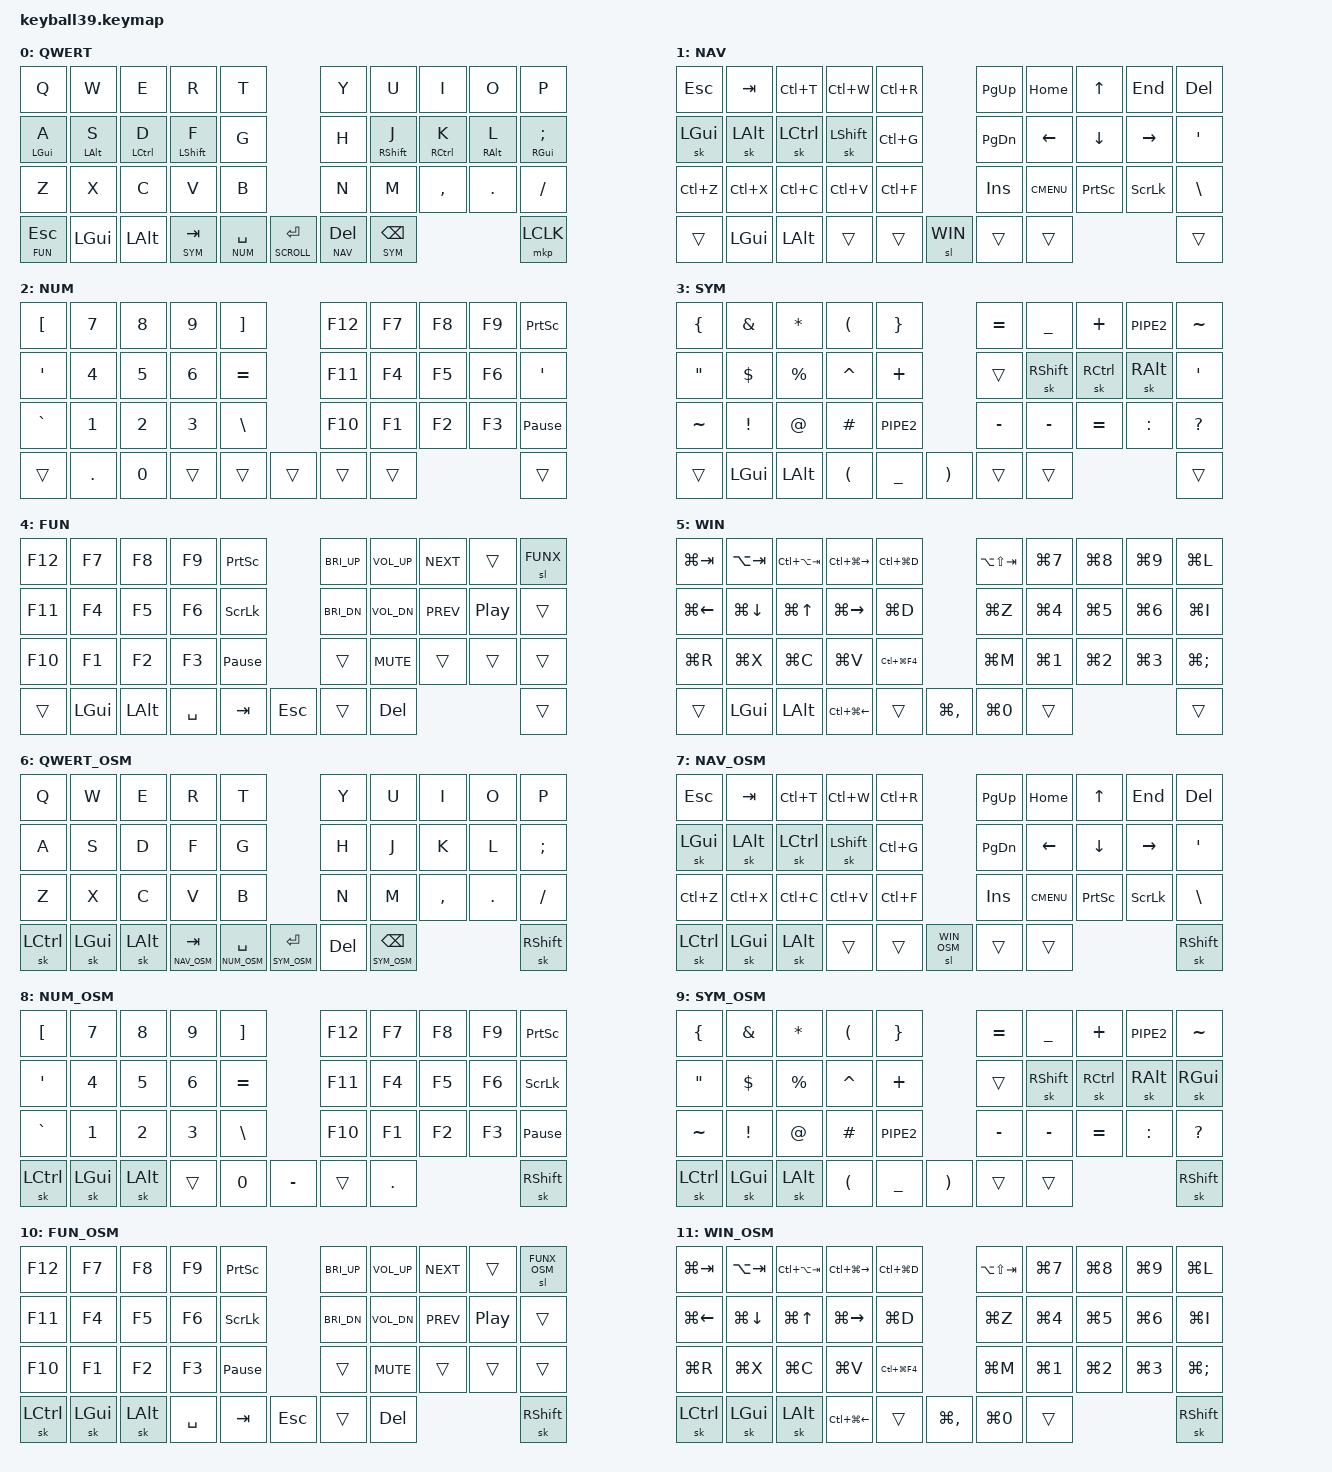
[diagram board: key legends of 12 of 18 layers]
/*
 * Copyright (c) 2020 The ZMK Contributors
 *
 * SPDX-License-Identifier: MIT
 */

#include <behaviors/mouse_keys.dtsi>
#include <dt-bindings/zmk/mouse.h>
#include <behaviors.dtsi>
#include <dt-bindings/zmk/keys.h>
#include <dt-bindings/zmk/bt.h>


// Layer definitions
#define BASE        0
#define NAV         1
#define NUM         2
#define SYM         3
#define FUN         4
#define WIN         5
#define BASE_OSM    6
#define NAV_OSM     7
#define NUM_OSM     8
#define SYM_OSM     9
#define FUN_OSM     10
#define WIN_OSM     11
#define FUNX        12
#define FUNX_OSM    13
#define ADJ         14
#define MOUSE       15
#define SCROLL      16
#define SNIPE       17



// Enhanced behavior configurations
&lt {
    tapping-term-ms = <180>;
    flavor = "balanced";
    quick-tap-ms = <180>;
    global-quick-tap;
};

&mt {
    tapping-term-ms = <180>;
    flavor = "balanced";
    quick-tap-ms = <180>;
    global-quick-tap;
    retro-tap;
};

&sk {
    release-after-ms = <2000>;
    quick-release;
};


/ {
    combos {
        compatible = "zmk,combos";

        // Universal escape
        combo_esc {
            timeout-ms = <40>;
            key-positions = <8 9>;
            bindings = <&kp ESC>;
        };

        // Quick tab access
        combo_tab {
            timeout-ms = <40>;
            key-positions = <0 1>;
            bindings = <&kp TAB>;
        };

        // Quick delete
        combo_del {
            timeout-ms = <40>;
            key-positions = <17 18>;
            bindings = <&kp DEL>;
        };


        // Programming brackets
        combo_lbkt {
            timeout-ms = <30>;
            key-positions = <3 4>;
            bindings = <&kp LBKT>;
        };

        combo_rbkt {
            timeout-ms = <30>;
            key-positions = <5 6>;
            bindings = <&kp RBKT>;
        };

        combo_lbrc {
            timeout-ms = <30>;
            key-positions = <13 14>;
            bindings = <&kp LBRC>;
        };
        combo_rbrc {
            timeout-ms = <30>;
            key-positions = <15 16>;
            bindings = <&kp RBRC>;
        };

        combo_lpar {
            timeout-ms = <30>;
            key-positions = <23 24>;
            bindings = <&kp LPAR>;
        };

        combo_rpar {
            timeout-ms = <30>;
            key-positions = <25 26>;
            bindings = <&kp RPAR>;
        };


        // Alt+Tab shortcuts
        combo_alt_tab {
            timeout-ms = <40>;
            key-positions = <1 2>;
            bindings = <&kp LA(TAB)>;
        };

        combo_alt_shift_tab {
            timeout-ms = <40>;
            key-positions = <2 3>;
            bindings = <&kp LA(LS(TAB))>;
        };
        // Windows shortcuts
        combo_win_left {
            timeout-ms = <30>;
            key-positions = <6 7>;
            bindings = <&kp LG(LEFT)>;
            layers = <NAV NAV_OSM>;
        };

        combo_win_right {
            timeout-ms = <30>;
            key-positions = <7 8>;
            bindings = <&kp LG(RIGHT)>;
            layers = <NAV NAV_OSM>;
        };

        // Windows management layer
        combo_win_layer {
            timeout-ms = <50>;
            key-positions = <34 35>;
            bindings = <&sl WIN>;
            layers = <BASE NAV NUM SYM FUN FUNX>;
        };

        combo_win_layer_osm {
            timeout-ms = <50>;
            key-positions = <34 35>;
            bindings = <&sl WIN_OSM>;
            layers = <BASE_OSM NAV_OSM NUM_OSM SYM_OSM FUN_OSM FUNX_OSM>;
        };

        // Adjustment layer
        combo_adj {
            timeout-ms = <50>;
            key-positions = <36 37>;
            bindings = <&mo ADJ>;
        };

        // Emergency return
        combo_base_return {
            timeout-ms = <100>;
            key-positions = <0 9>;
            bindings = <&to BASE>;
        };

        // Mouse click combos
        combo_left_click {
            timeout-ms = <50>;
            key-positions = <26 27>;  // N+M
            bindings = <&mkp LCLK>;
        };

        combo_right_click {
            timeout-ms = <50>;
            key-positions = <27 28>;  // M+,
            bindings = <&mkp RCLK>;
        };

        combo_middle_click {
            timeout-ms = <50>;
            key-positions = <26 27 28>;  // N+M+,
            bindings = <&mkp MCLK>;
        };

                // Adjustment layer
        combo_scroll {
            timeout-ms = <50>;
            key-positions = <26 17 28>;
            bindings = <&mo SCROLL>;
        };
                        // Adjustment layer
        combo_snipe {
            timeout-ms = <50>;
            key-positions = <26 27 28 29>;
            bindings = <&mo SNIPE>;
        };


        // Mouse click combos
        combo_left_clickL {
            timeout-ms = <50>;
            key-positions = <22 23>;  // N+M
            bindings = <&mkp LCLK>;
        };

        combo_right_clickL {
            timeout-ms = <50>;
            key-positions = <21 22>;  // M+,
            bindings = <&mkp RCLK>;
        };

        combo_middle_clickL {
            timeout-ms = <50>;
            key-positions = <21 22 23>;  // N+M+,
            bindings = <&mkp MCLK>;
        };

                // Adjustment layer
        combo_scrollL {
            timeout-ms = <50>;
            key-positions = <21 12 23>;
            bindings = <&mo SCROLL>;
        };
                        // Adjustment layer
        combo_snipeL {
            timeout-ms = <50>;
            key-positions = <20 21 22 23>;
            bindings = <&mo SNIPE>;
        };


    };

    macros {
        // Programming shortcuts
        arrow_fn: arrow_fn {
            compatible = "zmk,behavior-macro";
            #binding-cells = <0>;
            bindings = <&kp EQUAL &kp GT &kp SPACE>;
        };

        console_log: console_log {
            compatible = "zmk,behavior-macro";
            #binding-cells = <0>;
            bindings = <&kp C &kp O &kp N &kp S &kp O &kp L &kp E &kp DOT &kp L &kp O &kp G &kp LPAR>;
        };

        // Windows shortcuts
        win_run: win_run {
            compatible = "zmk,behavior-macro";
            #binding-cells = <0>;
            bindings = <&kp LG(R)>;
        };

        win_settings: win_settings {
            compatible = "zmk,behavior-macro";
            #binding-cells = <0>;
            bindings = <&kp LG(I)>;
        };

        win_lock: win_lock {
            compatible = "zmk,behavior-macro";
            #binding-cells = <0>;
            bindings = <&kp LG(L)>;
        };

        // Media control macros
        teams_mute: teams_mute {
            compatible = "zmk,behavior-macro";
            #binding-cells = <0>;
            bindings = <&kp LC(LS(M))>;
        };

        spotify_play_pause: spotify_play_pause {
            compatible = "zmk,behavior-macro";
            #binding-cells = <0>;
            bindings = <&kp C_PP>;
        };

        discord_mute: discord_mute {
            compatible = "zmk,behavior-macro";
            #binding-cells = <0>;
            bindings = <&kp LC(LS(M))>;
        };

        discord_deafen: discord_deafen {
            compatible = "zmk,behavior-macro";
            #binding-cells = <0>;
            bindings = <&kp LC(LS(D))>;
        };

        obs_start_stop: obs_start_stop {
            compatible = "zmk,behavior-macro";
            #binding-cells = <0>;
            bindings = <&kp F13>;
        };

        obs_pause: obs_pause {
            compatible = "zmk,behavior-macro";
            #binding-cells = <0>;
            bindings = <&kp F14>;
        };
    };

    keymap {
        compatible = "zmk,keymap";

        // Base layer with home row mods
        base_layer {
            label = "QWERT";
            bindings = <
&kp Q           &kp W           &kp E            &kp R             &kp T                                    &kp Y         &kp U             &kp I            &kp O           &kp P
&mt LGUI A      &mt LALT S      &mt LCTRL D      &mt LSHFT F       &kp G                                    &kp H         &mt RSHFT J       &mt RCTRL K      &mt RALT L      &mt RGUI SEMI
&kp Z           &kp X           &kp C            &kp V             &kp B                                    &kp N         &kp M             &kp COMMA        &kp DOT         &kp FSLH
&lt FUN ESC     &kp LGUI        &kp LALT         &lt SYM TAB       &lt NUM SPACE       &lt SCROLL RET       &lt NAV DEL       &lt SYM BSPC                                   &mkp LCLK
            >;
        };

        nav_layer {
            label = "NAV";
            bindings = <
&kp ESC         &kp TAB         &kp LC(T)        &kp LC(W)         &kp LC(R)                                &kp PG_UP     &kp HOME          &kp UP           &kp END         &kp DEL
&sk LGUI        &sk LALT        &sk LCTRL        &sk LSHFT         &kp LC(G)                                &kp PG_DN     &kp LEFT          &kp DOWN         &kp RIGHT       &kp SQT
&kp LC(Z)       &kp LC(X)       &kp LC(C)        &kp LC(V)         &kp LC(F)                                &kp INS       &kp K_CMENU       &kp PSCRN        &kp SCROLLLOCK  &kp BSLH
&trans          &kp LGUI        &kp LALT         &trans            &trans               &sl WIN             &trans        &trans                                             &trans
            >;
        };

        num_layer {
            label = "NUM";
            bindings = <
&kp LBKT        &kp N7          &kp N8           &kp N9            &kp RBKT                                 &kp F12       &kp F7            &kp F8           &kp F9          &kp PSCRN
&kp SQT         &kp N4          &kp N5           &kp N6            &kp EQUAL                                &kp F11       &kp F4            &kp F5           &kp F6          &kp SQT
&kp GRAVE       &kp N1          &kp N2           &kp N3            &kp BSLH                                 &kp F10       &kp F1            &kp F2           &kp F3          &kp PAUSE_BREAK
&trans          &kp DOT         &kp N0           &trans            &trans               &trans              &trans        &trans                                             &trans
            >;
        };

        sym_layer {
            label = "SYM";
            bindings = <
&kp LBRC        &kp AMPERSAND   &kp ASTERISK     &kp LPAR          &kp RBRC                                 &kp EQUAL     &kp UNDERSCORE    &kp PLUS         &kp PIPE2       &kp TILDE
&kp DQT         &kp DLLR        &kp PRCNT        &kp CARET         &kp PLUS                                 &trans        &sk RSHFT         &sk RCTRL        &sk RALT        &kp SQT
&kp TILDE       &kp EXCL        &kp AT           &kp HASH          &kp PIPE2                                &kp MINUS     &kp MINUS         &kp EQUAL        &kp COLON       &kp QMARK
&trans          &kp LGUI        &kp LALT         &kp LPAR          &kp UNDERSCORE       &kp RPAR            &trans        &trans                                         &trans
            >;
        };

        fun_layer {
            label = "FUN";
            bindings = <
&kp F12         &kp F7          &kp F8           &kp F9            &kp PSCRN                                &kp C_BRI_UP  &kp C_VOL_UP      &kp C_NEXT       &trans          &sl FUNX
&kp F11         &kp F4          &kp F5           &kp F6            &kp SLCK                                 &kp C_BRI_DN  &kp C_VOL_DN      &kp C_PREV       &kp C_PP        &trans
&kp F10         &kp F1          &kp F2           &kp F3            &kp PAUSE_BREAK                          &trans        &kp C_MUTE        &trans           &trans          &trans
&trans          &kp LGUI        &kp LALT         &kp SPACE         &kp TAB              &kp ESC             &trans        &kp DEL                                        &trans
            >;
        };

        win_layer {
            label = "WIN";
            bindings = <
&kp LG(TAB)     &kp LA(TAB)     &kp LC(LA(TAB))  &kp LC(LG(RIGHT)) &kp LC(LG(D))                            &kp LA(LS(TAB)) &kp LG(N7)      &kp LG(N8)       &kp LG(N9)      &kp LG(L)
&kp LG(LEFT)    &kp LG(DOWN)    &kp LG(UP)       &kp LG(RIGHT)     &kp LG(D)                                &kp LG(Z)     &kp LG(N4)        &kp LG(N5)       &kp LG(N6)      &kp LG(I)
&kp LG(R)       &kp LG(X)       &kp LG(C)        &kp LG(V)         &kp LC(LG(F4))                           &kp LG(M)     &kp LG(N1)        &kp LG(N2)       &kp LG(N3)      &kp LG(SEMI)
&trans          &kp LGUI        &kp LALT         &kp LC(LG(LEFT))  &trans               &kp LG(COMMA)       &kp LG(N0)    &trans                                         &trans
            >;
        };

        base_osm_layer {
            label = "QWERT_OSM";
            bindings = <
&kp Q           &kp W           &kp E            &kp R             &kp T                                    &kp Y         &kp U             &kp I            &kp O           &kp P
&kp A           &kp S           &kp D            &kp F             &kp G                                    &kp H         &kp J             &kp K            &kp L           &kp SEMI
&kp Z           &kp X           &kp C            &kp V             &kp B                                    &kp N         &kp M             &kp COMMA        &kp DOT         &kp FSLH
&sk LCTRL       &sk LGUI        &sk LALT         &lt NAV_OSM TAB   &lt NUM_OSM SPACE    &lt SYM_OSM RET     &kp DEL       &lt SYM_OSM BSPC                               &sk RSHFT
            >;
        };

        nav_osm_layer {
            label = "NAV_OSM";
            bindings = <
&kp ESC         &kp TAB         &kp LC(T)        &kp LC(W)         &kp LC(R)                                &kp PG_UP     &kp HOME          &kp UP           &kp END         &kp DEL
&sk LGUI        &sk LALT        &sk LCTRL        &sk LSHFT         &kp LC(G)                                &kp PG_DN     &kp LEFT          &kp DOWN         &kp RIGHT       &kp SQT
&kp LC(Z)       &kp LC(X)       &kp LC(C)        &kp LC(V)         &kp LC(F)                                &kp INS       &kp K_CMENU          &kp PSCRN        &kp SCROLLLOCK  &kp BSLH
&sk LCTRL       &sk LGUI        &sk LALT         &trans            &trans               &sl WIN_OSM         &trans        &trans                                         &sk RSHFT
            >;
        };

        num_osm_layer {
            label = "NUM_OSM";
            bindings = <
&kp LBKT        &kp N7          &kp N8           &kp N9            &kp RBKT                                 &kp F12       &kp F7            &kp F8           &kp F9          &kp PSCRN
&kp SQT         &kp N4          &kp N5           &kp N6            &kp EQUAL                                &kp F11       &kp F4            &kp F5           &kp F6          &kp SCROLLLOCK
&kp GRAVE       &kp N1          &kp N2           &kp N3            &kp BSLH                                 &kp F10       &kp F1            &kp F2           &kp F3          &kp PAUSE_BREAK
&sk LCTRL       &sk LGUI        &sk LALT         &trans            &kp N0               &kp MINUS           &trans        &kp DOT                                        &sk RSHFT
            >;
        };

        sym_osm_layer {
            label = "SYM_OSM";
            bindings = <
&kp LBRC        &kp AMPERSAND   &kp ASTERISK     &kp LPAR          &kp RBRC                                 &kp EQUAL     &kp UNDERSCORE    &kp PLUS         &kp PIPE2       &kp TILDE
&kp DOUBLE_QUOTES &kp DOLLAR    &kp PERCENT      &kp CARET         &kp PLUS                                 &trans        &sk RSHFT         &sk RCTRL        &sk RALT        &sk RGUI
&kp TILDE       &kp EXCL        &kp AT           &kp HASH          &kp PIPE2                                &kp MINUS     &kp MINUS         &kp EQUAL        &kp COLON       &kp QUESTION
&sk LCTRL       &sk LGUI        &sk LALT         &kp LPAR          &kp UNDERSCORE       &kp RPAR            &trans        &trans                                         &sk RSHFT
            >;
        };

        fun_osm_layer {
            label = "FUN_OSM";
            bindings = <
&kp F12         &kp F7          &kp F8           &kp F9            &kp PSCRN                                &kp C_BRI_UP  &kp C_VOL_UP      &kp C_NEXT       &trans          &sl FUNX_OSM
&kp F11         &kp F4          &kp F5           &kp F6            &kp SCROLLLOCK                           &kp C_BRI_DN  &kp C_VOL_DN      &kp C_PREV       &kp C_PP        &trans
&kp F10         &kp F1          &kp F2           &kp F3            &kp PAUSE_BREAK                          &trans        &kp C_MUTE        &trans           &trans          &trans
&sk LCTRL       &sk LGUI        &sk LALT         &kp SPACE         &kp TAB              &kp ESC             &trans        &kp DEL                                        &sk RSHFT
            >;
        };

        win_osm_layer {
            label = "WIN_OSM";
            bindings = <
&kp LG(TAB)     &kp LA(TAB)     &kp LC(LA(TAB))  &kp LC(LG(RIGHT)) &kp LC(LG(D))                            &kp LA(LS(TAB)) &kp LG(N7)      &kp LG(N8)       &kp LG(N9)      &kp LG(L)
&kp LG(LEFT)    &kp LG(DOWN)    &kp LG(UP)       &kp LG(RIGHT)     &kp LG(D)                                &kp LG(Z)     &kp LG(N4)        &kp LG(N5)       &kp LG(N6)      &kp LG(I)
&kp LG(R)       &kp LG(X)       &kp LG(C)        &kp LG(V)         &kp LC(LG(F4))                           &kp LG(M)     &kp LG(N1)        &kp LG(N2)       &kp LG(N3)      &kp LG(SEMI)
&sk LCTRL       &sk LGUI        &sk LALT         &kp LC(LG(LEFT))  &trans               &kp LG(COMMA)       &kp LG(N0)    &trans                                         &sk RSHFT
            >;
        };

        funx_layer {
            label = "FUNX";
            bindings = <
&kp F24         &kp F19         &kp F20          &kp F21           &kp F22                                  &kp F23       &kp LC(LS(M))     &kp C_PP         &kp LC(LS(M))   &kp F13
&kp F18         &kp F15         &kp F16          &kp F17           &kp F18                                  &kp F19       &kp F20           &kp F21          &kp LC(LS(D))   &kp F14
&kp F13         &kp F14         &kp F15          &kp F16           &kp F17                                  &kp F18       &kp F19           &kp F20          &kp F21         &kp F22
&trans          &kp LGUI        &kp LALT         &trans            &trans               &trans              &trans        &trans                                         &trans
            >;
        };

        funx_osm_layer {
            label = "FUNX_OSM";
            bindings = <
&kp F24         &kp F19         &kp F20          &kp F21           &kp F22                                  &kp F23       &kp LC(LS(M))     &kp C_PP         &kp LC(LS(M))   &kp F13
&kp F18         &kp F15         &kp F16          &kp F17           &kp F18                                  &kp F19       &kp F20           &kp F21          &kp LC(LS(D))   &kp F14
&kp F13         &kp F14         &kp F15          &kp F16           &kp F17                                  &kp F18       &kp F19           &kp F20          &kp F21         &kp F22
&sk LCTRL       &sk LGUI        &sk LALT         &trans            &trans               &trans              &trans        &trans                                         &sk RSHFT
            >;
        };

        adj_layer {
            label = "ADJ";
            bindings = <
&bootloader     &trans          &trans           &trans            &to BASE                                 &to BASE_OSM  &trans            &trans           &trans          &bootloader
&bt BT_CLR      &bt BT_SEL 0    &bt BT_SEL 1     &bt BT_SEL 2      &bt BT_SEL 3                             &kp C_BRI_DN  &kp C_BRI_UP      &kp C_VOL_DN     &kp C_VOL_UP    &kp C_MUTE
&sys_reset      &trans          &trans           &trans            &trans                                   &trans        &trans            &trans           &trans          &sys_reset
&trans          &trans          &trans           &trans            &trans               &trans              &trans        &trans                                         &trans
            >;
        };
        mouse_layer {
            label = "MOUSE";
            bindings = <
&kp N1          &kp N2          &kp N3        &kp N4     &kp N5                  &kp N6         &kp N7     &kp N8  &kp N9     &kp N0
&kp LGUI        &kp LALT        &kp LCTRL        &kp LSHFT         &kp LC(C)     &kp LC(C) &kp RSHFT         &kp RCTRL        &kp RALT        &kp RGUI         
&mkp MCLK  &mkp RCLK          &none          &mkp LCLK     &kp LC(V)                  &kp LC(V)  &mkp LCLK  &none   &mkp RCLK  &mkp MCLK
&none           &trans          &trans        &trans     &trans  &trans  &trans  &trans                                        &none
            >;
        };

        scroll_layer {
            label = "SCROLL";
            bindings = <
&trans  &kp HOME      &kp UP_ARROW    &kp END       &kp PAGE_UP                  &kp PAGE_UP  &trans  &kp LC(LG(UP))  &trans  &trans
&trans  &kp LEFT_ARROW  &kp DOWN_ARROW  &kp RIGHT    &kp PAGE_DOWN                  &kp PAGE_DOWN  &kp LC(LG(LEFT))  &kp LC(LG(DOWN))  &kp LC(LG(RIGHT))  &trans
&trans  &trans  &trans  &trans  &trans                                     &trans  &trans  &trans  &trans  &trans
&trans  &trans  &trans  &trans  &trans  &trans  &trans                     &trans                          &trans
            >;
        };        


        snipe_layer {
            label = "SNIPE";
            bindings = <
&trans  &kp HOME      &kp UP_ARROW    &kp END       &trans                  &kp PAGE_UP  &trans  &kp LC(LG(UP))  &trans  &trans
&trans  &kp LEFT_ARROW  &kp DOWN_ARROW  &kp RIGHT    &trans                  &kp PAGE_DOWN  &kp LC(LG(LEFT))  &kp LC(LG(DOWN))  &kp LC(LG(RIGHT))  &trans
&trans  &trans  &trans  &trans  &trans                                     &trans  &trans  &trans  &trans  &trans
&trans  &trans  &trans  &trans  &trans  &trans  &trans                     &trans                          &trans
            >;
        };        
    };

};
